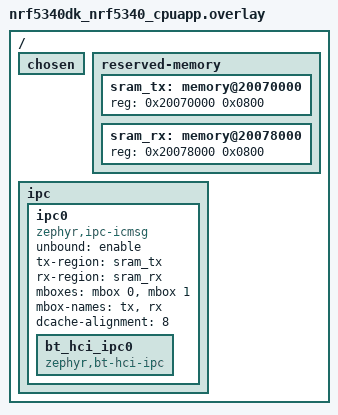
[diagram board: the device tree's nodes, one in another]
/*
 * Copyright (c) 2022 Nordic Semiconductor ASA
 *
 * SPDX-License-Identifier: Apache-2.0
 */

/ {
	chosen {
		/delete-property/ zephyr,ipc_shm;
	};

	reserved-memory {
		/delete-node/ memory@20070000;

		sram_tx: memory@20070000 {
			reg = <0x20070000 0x0800>;
		};

		sram_rx: memory@20078000 {
			reg = <0x20078000 0x0800>;
		};
	};

	ipc {
		/delete-node/ ipc0;

		ipc0: ipc0 {
			compatible = "zephyr,ipc-icmsg";
			unbound = "enable";
			tx-region = <&sram_tx>;
			rx-region = <&sram_rx>;
			mboxes = <&mbox 0>, <&mbox 1>;
			mbox-names = "tx", "rx";
			status = "okay";
			dcache-alignment = <8>;

			bt_hci_ipc0: bt_hci_ipc0 {
				compatible = "zephyr,bt-hci-ipc";
				status = "okay";
			};
		};
	};
};
